# ATSAME70N20B register map
Vendor: Microchip Technology; Series: SAME70; File version: 0
CPU: CM7 r1p1, little endian, MPU, FPU, 3 interrupt priority bits
Registers are 32-bit, read-write, reset 0x0 unless marked. A register's access mark holds for its fields unless they carry their own. Offsets are from the block's base; [hi:lo] are bit positions; {n}, {i} and the like mark numbered series.

## UTMI — USB Transmitter Interface Macrocell
Base 0x400E0400; register names take the prefix UTMI_
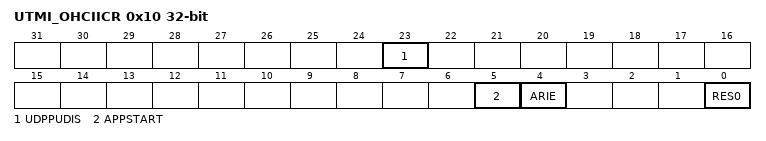
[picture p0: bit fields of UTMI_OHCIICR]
0x10 UTMI_OHCIICR — OHCI Interrupt Configuration Register
  [23] UDPPUDIS — USB Device Pull-up Disable
  [5] APPSTART
  [4] ARIE — OHCI Asynchronous Resume Interrupt Enable
  [0] RES0 — USB PORTx Reset
0x30 UTMI_CKTRIM — UTMI Clock Trimming Register
  [1:0] FREQ — UTMI Reference Clock Frequency
    0=XTAL12 (12 MHz reference clock); 1=XTAL16 (16 MHz reference clock)

## WDT — Watchdog Timer
Base 0x400E1850; register names take the prefix WDT_
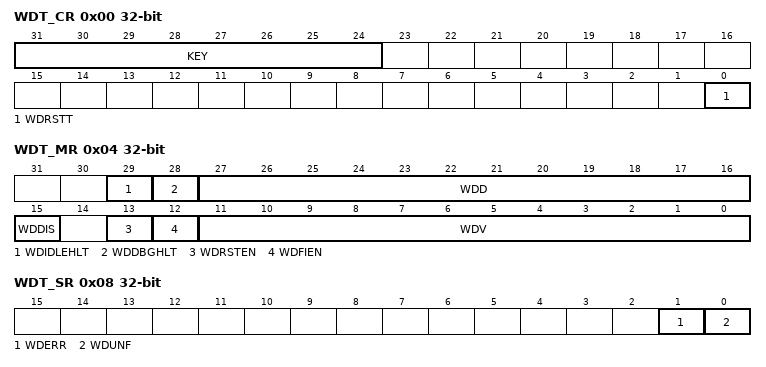
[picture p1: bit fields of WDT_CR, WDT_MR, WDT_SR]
0x00 WDT_CR wo — Control Register
  [31:24] KEY — Password
    165=PASSWD (Writing any other value in this field aborts the write operation.)
  [0] WDRSTT — Watchdog Restart
0x04 WDT_MR — Mode Register
  [29] WDIDLEHLT — Watchdog Idle Halt
  [28] WDDBGHLT — Watchdog Debug Halt
  [27:16] WDD — Watchdog Delta Value
  [15] WDDIS — Watchdog Disable
  [13] WDRSTEN — Watchdog Reset Enable
  [12] WDFIEN — Watchdog Fault Interrupt Enable
  [11:0] WDV — Watchdog Counter Value
0x08 WDT_SR ro — Status Register
  [1] WDERR — Watchdog Error (cleared on read)
  [0] WDUNF — Watchdog Underflow (cleared on read)

## LOCKBIT
Base 0x00000000; register names take the prefix LOCKBIT_
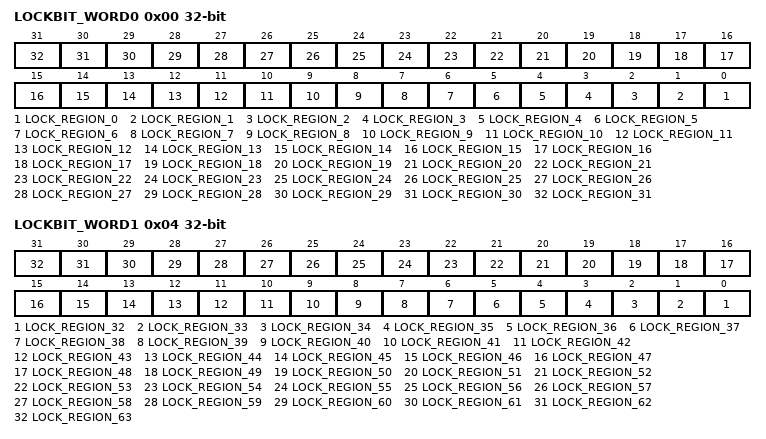
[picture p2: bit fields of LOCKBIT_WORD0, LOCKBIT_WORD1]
0x00 LOCKBIT_WORD0 — Lock Bits Word 0
  [n] LOCK_REGION_{n} (n=0..31)
0x04 LOCKBIT_WORD1 — Lock Bits Word 1
  [n-32] LOCK_REGION_{n} (n=32..63)

## SCnSCB — System control not in SCB
Base 0xE000E000; register names take the prefix SCnSCB_
0x04 ICTR ro — Interrupt Controller Type Register
  [3:0] INTLINESNUM — Total number of interrupt lines supported by an implementation, defined in groups of 32
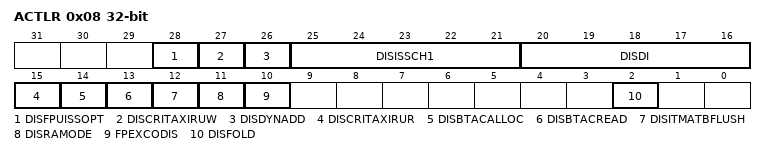
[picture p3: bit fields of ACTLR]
0x08 ACTLR — Auxiliary Control Register
  [28] DISFPUISSOPT — Disables dynamic allocation of ADD and SUB instructions
  [27] DISCRITAXIRUW — Disable critical AXI read-under-write
  [26] DISDYNADD — Disables dynamic allocation of ADD and SUB instructions
  [25:21] DISISSCH1
  [20:16] DISDI
  [15] DISCRITAXIRUR
  [14] DISBTACALLOC
  [13] DISBTACREAD
  [12] DISITMATBFLUSH — Disables ITM and DWT ATB flush
  [11] DISRAMODE — Disables dynamic read allocate mode for Write-Back Write-Allocate memory regions
  [10] FPEXCODIS — Disables FPU exception outputs
  [2] DISFOLD — Disables folding of IT instructions

## SysTick — System timer
Base 0xE000E010; register names take the prefix SysTick_
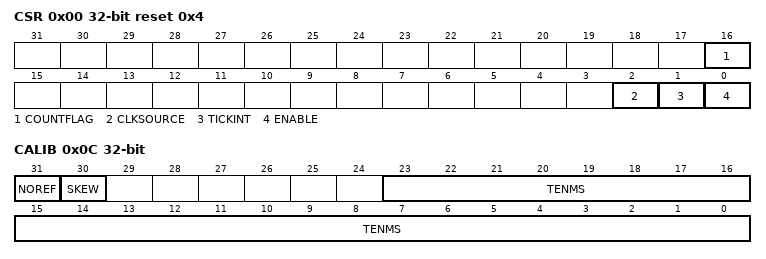
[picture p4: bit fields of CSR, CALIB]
0x00 CSR reset 0x4 — Control and Status Register
  [16] COUNTFLAG — Returns 1 if timer counted to 0 since last time this was read
  [2] CLKSOURCE — Indicates the clock source
    0=external clock; 1=processor clock
  [1] TICKINT — Enables SysTick exception request
    0=counting down to 0 does not assert the SysTick exception request; 1=counting down to 0 asserts the SysTick exception request
  [0] ENABLE — Enables the counter
    0=counter disabled; 1=counter enabled
0x04 RVR — Reload Value Register
  [23:0] RELOAD — Value to load into the SysTick Current Value Register when the counter reaches 0
0x08 CVR — Current Value Register
  [23:0] CURRENT — Current value at the time the register is accessed
0x0C CALIB ro — Calibration Value Register
  [31] NOREF — Indicates whether the device provides a reference clock to the processor
    0=The reference clock is provided; 1=The reference clock is not provided
  [30] SKEW — Indicates whether the TENMS value is exact
    0=10ms calibration value is exact; 1=10ms calibration value is inexact, because of the clock frequency
  [23:0] TENMS — Reload value to use for 10ms timing

## NVIC — Nested Vectored Interrupt Controller
Base 0xE000E100; register names take the prefix NVIC_
{0x0+4i} ISER[{i}] (i=0..7) — Interrupt Set Enable Register n
  [31:0] SETENA — Interrupt set enable bits
{0x80+4i} ICER[{i}] (i=0..7) — Interrupt Clear Enable Register n
  [31:0] CLRENA — Interrupt clear-enable bits
{0x100+4i} ISPR[{i}] (i=0..7) — Interrupt Set Pending Register n
  [31:0] SETPEND — Interrupt set-pending bits
{0x180+4i} ICPR[{i}] (i=0..7) — Interrupt Clear Pending Register n
  [31:0] CLRPEND — Interrupt clear-pending bits
{0x200+4i} IABR[{i}] (i=0..7) — Interrupt Active bit Register n
  [31:0] ACTIVE — Interrupt active flags
{0x300+i} IP[{i}] (i=0..239) 8-bit — Interrupt Priority Register (8Bit wide) n
  [7:0] PRI0 — Priority of interrupt 0
0xE00 STIR wo — Software Trigger Interrupt Register
  [8:0] INTID — Interrupt ID of the interrupt to trigger, in the range 0-239. For example, a value of 0x03 specifies interrupt IRQ3.
